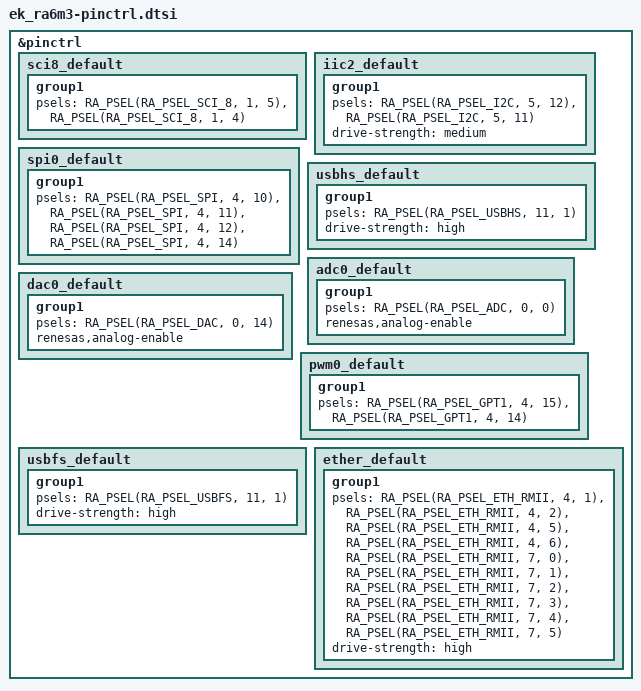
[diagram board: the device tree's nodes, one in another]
/*
 * Copyright (c) 2024-2025 Renesas Electronics Corporation
 * SPDX-License-Identifier: Apache-2.0
 */

&pinctrl {
	sci8_default: sci8_default {
		group1 {
			/* tx rx */
			psels = <RA_PSEL(RA_PSEL_SCI_8, 1, 5)>,
			<RA_PSEL(RA_PSEL_SCI_8, 1, 4)>;
		};
	};

	iic2_default: iic2_default {
		group1 {
			/* SCL2 SDA2 */
			psels = <RA_PSEL(RA_PSEL_I2C, 5, 12)>,
			<RA_PSEL(RA_PSEL_I2C, 5, 11)>;
			drive-strength = "medium";
		};
	};

	spi0_default: spi0_default {
		group1 {
			/* MISO MOSI RSPCK SSL */
			psels = <RA_PSEL(RA_PSEL_SPI, 4, 10)>,
			<RA_PSEL(RA_PSEL_SPI, 4, 11)>,
			<RA_PSEL(RA_PSEL_SPI, 4, 12)>,
			<RA_PSEL(RA_PSEL_SPI, 4, 14)>;
		};
	};

	usbhs_default: usbhs_default {
		group1 {
			psels = <RA_PSEL(RA_PSEL_USBHS, 11, 1)>; /* VBUS */
			drive-strength = "high";
		};
	};

	adc0_default: adc0_default {
		group1 {
			/* input */
			psels = <RA_PSEL(RA_PSEL_ADC, 0, 0)>;
			renesas,analog-enable;
		};
	};

	dac0_default: dac0_default {
		group1 {
			/* output */
			psels = <RA_PSEL(RA_PSEL_DAC, 0, 14)>;
			renesas,analog-enable;
		};
	};

	pwm0_default: pwm0_default {
		group1 {
			/* GTIOC0A GTIOC0B */
			psels = <RA_PSEL(RA_PSEL_GPT1, 4, 15)>,
				<RA_PSEL(RA_PSEL_GPT1, 4, 14)>;
		};
	};

	usbfs_default: usbfs_default {
		group1 {
			/* USB_VBUS */
			psels = <RA_PSEL(RA_PSEL_USBFS, 11, 1)>;
			drive-strength = "high";
		};
	};

	ether_default: ether_default {
		group1 {
			psels = <RA_PSEL(RA_PSEL_ETH_RMII, 4, 1)>, /* ET0_MDC */
				<RA_PSEL(RA_PSEL_ETH_RMII, 4, 2)>, /* ET0_MDIO */
				<RA_PSEL(RA_PSEL_ETH_RMII, 4, 5)>, /* RMII0_TXD_EN_B */
				<RA_PSEL(RA_PSEL_ETH_RMII, 4, 6)>, /* RMII0_TXD1_BR */
				<RA_PSEL(RA_PSEL_ETH_RMII, 7, 0)>, /* RMII0_TXD0_B */
				<RA_PSEL(RA_PSEL_ETH_RMII, 7, 1)>, /* REF50CK0_B */
				<RA_PSEL(RA_PSEL_ETH_RMII, 7, 2)>, /* RMII0_RXD0_B */
				<RA_PSEL(RA_PSEL_ETH_RMII, 7, 3)>, /* RMII0_RXD1_B */
				<RA_PSEL(RA_PSEL_ETH_RMII, 7, 4)>, /* RMII0_RX_ER_B */
				<RA_PSEL(RA_PSEL_ETH_RMII, 7, 5)>; /* RMII0_CRS_DV_B */
			drive-strength = "high";
		};
	};
};
